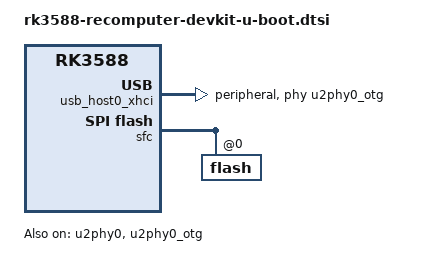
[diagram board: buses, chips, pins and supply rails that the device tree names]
#include "rk3588-u-boot.dtsi"

/* Make the non-power USB port work with gadget/UMS */
&u2phy0 {
	status = "okay";
};

&u2phy0_otg {
	status = "okay";
};

&usb_host0_xhci {
	dr_mode = "peripheral";
	maximum-speed = "high-speed";
	phys = <&u2phy0_otg>;
	phy-names = "usb2-phy";
	status = "okay";
};

/* For working SPI-flash */
&fspim2_pins {
	bootph-pre-ram;
	bootph-some-ram;
};

/* So the Recovery button can work */
&saradc {
	bootph-pre-ram;
	/* vdd-microvolts = <1800000>; */
};

&sfc {
	flash@0 {
		bootph-pre-ram;
		bootph-some-ram;
	};
};
